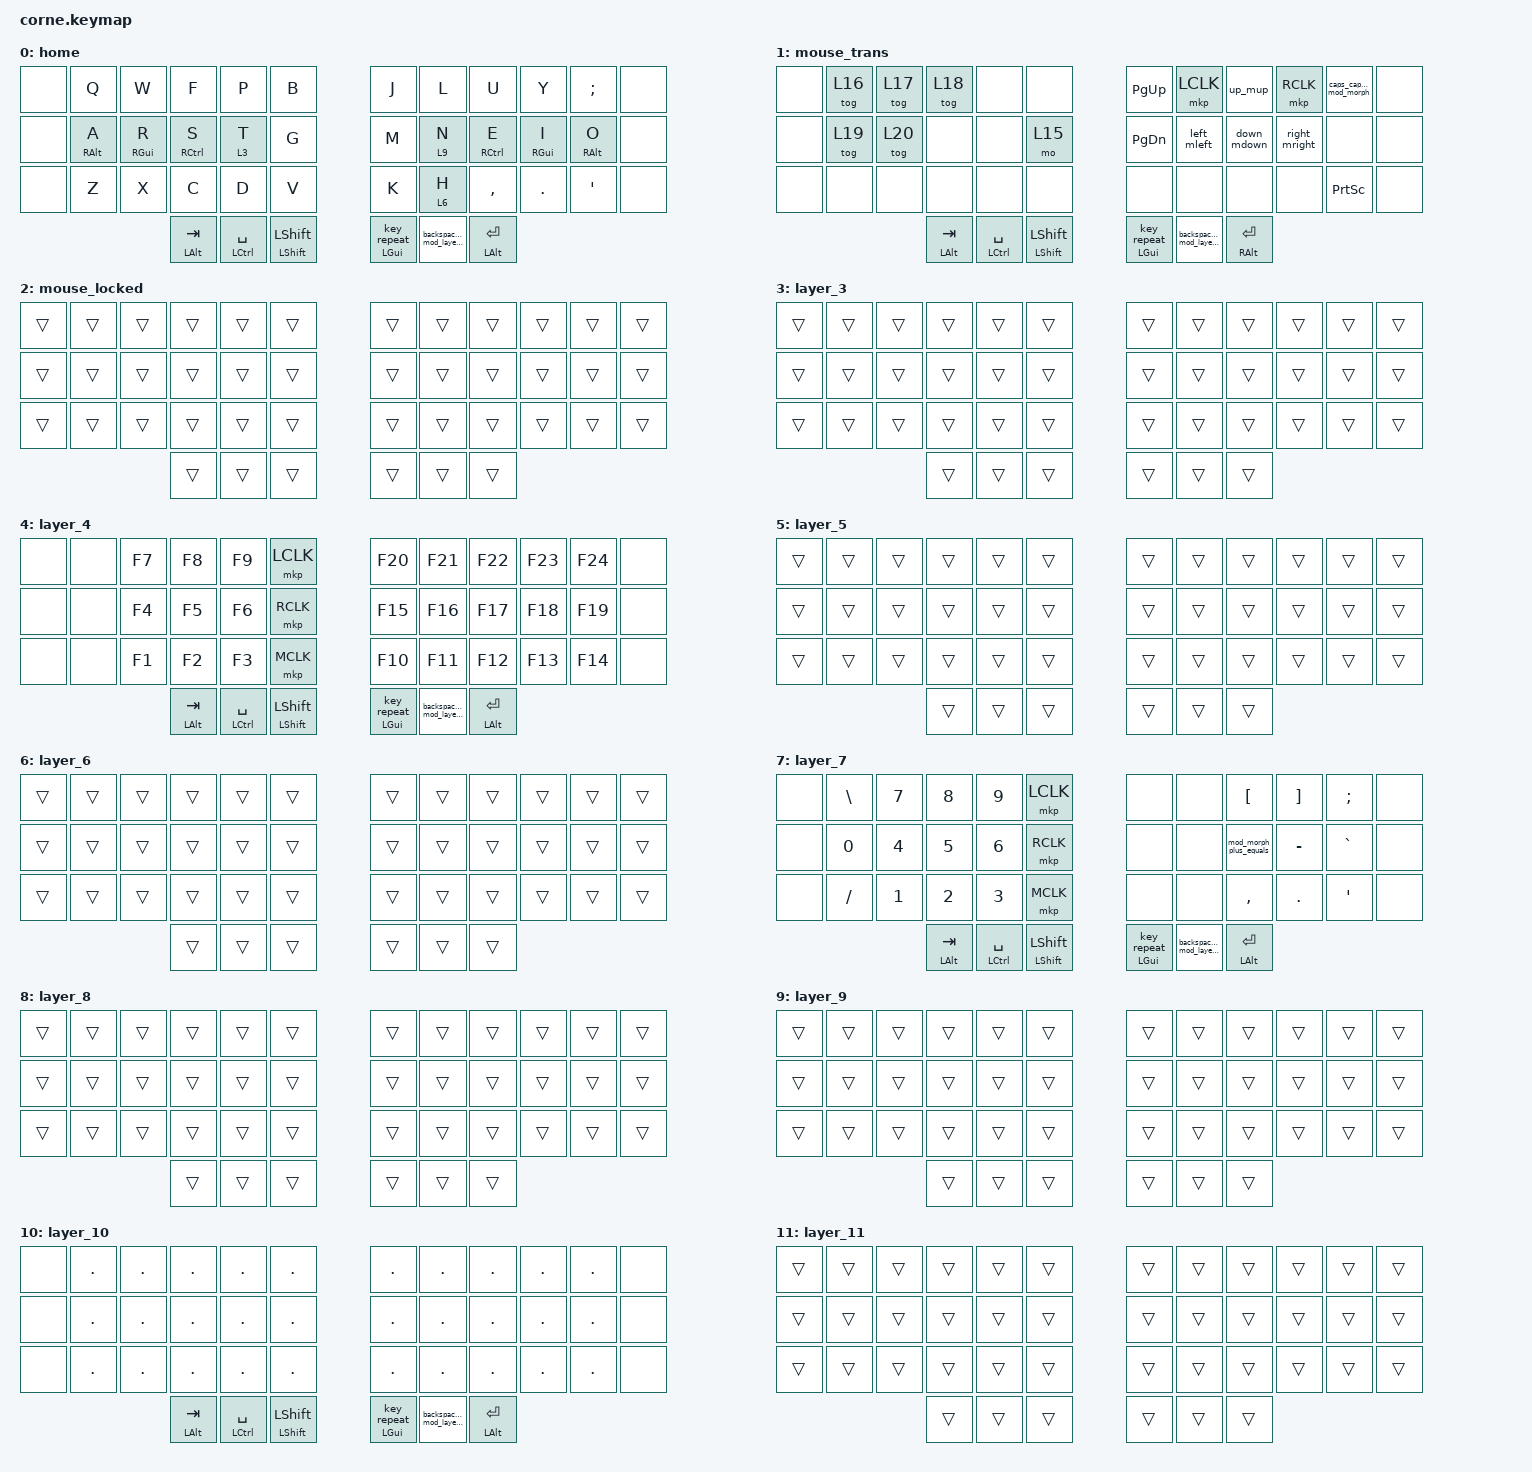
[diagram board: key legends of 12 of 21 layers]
/*
 * Copyright (c) 2020 The ZMK Contributors
 *
 * SPDX-License-Identifier: MIT
 */

#include <behaviors.dtsi>
#include <dt-bindings/zmk/bt.h>
#include <dt-bindings/zmk/keys.h>
#include <dt-bindings/zmk/mouse.h>

/ {
    behaviors {
        hold_tap_mo_kp: hold_tap_mo_kp {
            compatible = "zmk,behavior-hold-tap";
            label = "HOLD_TAP_MO_KP";
            bindings = <&mo>, <&kp>;

            #binding-cells = <2>;
            tapping-term-ms = <180>;
            flavor = "balanced";
            quick-tap-ms = <150>;
        };

        hold_tap_kp_kp: hold_tap_kp_kp {
            compatible = "zmk,behavior-hold-tap";
            label = "HOLD_TAP_KP_KP";
            bindings = <&kp>, <&kp>;

            #binding-cells = <2>;
            tapping-term-ms = <280>;
            flavor = "balanced";
            quick-tap-ms = <175>;
            require-prior-idle-ms = <135>;
            hold-while-undecided;
        };

        hold_tap_tog_kr: hold_tap_tog_kr {
            compatible = "zmk,behavior-hold-tap";
            label = "HOLD_TAP_TOG_KR";
            #binding-cells = <2>;
            tapping-term-ms = <280>;
            flavor = "balanced";
            bindings = <&tog>, <&key_repeat>;

            quick-tap-ms = <175>;
            require-prior-idle-ms = <135>;
            hold-while-undecided;
        };

        hold_tap_kp_kr: hold_tap_kp_kr {
            compatible = "zmk,behavior-hold-tap";
            label = "HOLD_TAP_KP_KR";
            #binding-cells = <2>;
            tapping-term-ms = <280>;
            flavor = "balanced";
            bindings = <&kp>, <&key_repeat>;

            quick-tap-ms = <175>;
            require-prior-idle-ms = <135>;
            hold-while-undecided;
        };

        sticky_key: sticky_key {
            compatible = "zmk,behavior-sticky-key";
            label = "STICKY_KEY";
            bindings = <&kp>;
            #binding-cells = <1>;
            quick-release;
            release-after-ms = <200>;
        };

        hold_tap_sk_kp: hold_tap_sk_kp {
            compatible = "zmk,behavior-hold-tap";
            label = "HOLD_TAP_SK_KP";
            bindings = <&sticky_key>, <&kp>;

            #binding-cells = <2>;
            tapping-term-ms = <280>;
            quick-tap-ms = <175>;
            flavor = "balanced";
            require-prior-idle-ms = <135>;
            hold-while-undecided;
        };

        hold_tap_kp_sk: hold_tap_kp_sk {
            compatible = "zmk,behavior-hold-tap";
            label = "HOLD_TAP_KP_SK";
            bindings = <&kp>, <&sticky_key>;

            #binding-cells = <2>;
            tapping-term-ms = <280>;
            flavor = "balanced";
            quick-tap-ms = <175>;
            require-prior-idle-ms = <135>;
            hold-while-undecided-linger;
        };

        hold_tap_tog_kp: hold_tap_tog_kp {
            compatible = "zmk,behavior-hold-tap";
            label = "HOLD_TAP_TOG_KP";
            bindings = <&tog>, <&kp>;

            #binding-cells = <2>;
            tapping-term-ms = <280>;
            flavor = "balanced";
            quick-tap-ms = <175>;
            require-prior-idle-ms = <135>;
            hold-while-undecided;
        };

        backspace_del_mod_layer_1: backspace_del_mod_layer_1 {
            compatible = "zmk,behavior-mod-morph";
            label = "BACKSPACE_DEL_MOD_LAYER_1";
            bindings = <&kp BACKSPACE>, <&kp DELETE>;

            #binding-cells = <0>;
            mods = <(MOD_LALT)>;
        };

        backspace_del_mod_layer_3: backspace_del_mod_layer_3 {
            compatible = "zmk,behavior-mod-morph";
            label = "BACKSPACE_DEL_MOD_LAYER_3";
            bindings =
                <&hold_tap_tog_kp 5 BACKSPACE>,
                <&hold_tap_tog_kp 5 DELETE>;

            #binding-cells = <0>;
            mods = <(MOD_LALT)>;
        };

        backspace_del_mod_layer_5: backspace_del_mod_layer_5 {
            compatible = "zmk,behavior-mod-morph";
            label = "BACKSPACE_DEL_MOD_LAYER_5";
            bindings =
                <&hold_tap_tog_kp 11 BACKSPACE>,
                <&hold_tap_tog_kp 11 DELETE>;

            #binding-cells = <0>;
            mods = <(MOD_LALT)>;
        };

        backspace_del_mod_layer_2: backspace_del_mod_layer_2 {
            compatible = "zmk,behavior-mod-morph";
            label = "BACKSPACE_DEL_MOD_LAYER_2";
            bindings =
                <&hold_tap_tog_kp 2 BACKSPACE>,
                <&hold_tap_tog_kp 2 DELETE>;

            #binding-cells = <0>;
            mods = <(MOD_LALT)>;
        };

        backspace_del_mod_layer_4: backspace_del_mod_layer_4 {
            compatible = "zmk,behavior-mod-morph";
            label = "BACKSPACE_DEL_MOD_LAYER_4";
            bindings =
                <&hold_tap_tog_kp 8 BACKSPACE>,
                <&hold_tap_tog_kp 8 DELETE>;

            #binding-cells = <0>;
            mods = <(MOD_LALT)>;
        };

        backspace_del_mod_layer_6: backspace_del_mod_layer_6 {
            compatible = "zmk,behavior-mod-morph";
            label = "BACKSPACE_DEL_MOD_LAYER_6";
            bindings =
                <&hold_tap_tog_kp 14 BACKSPACE>,
                <&hold_tap_tog_kp 14 DELETE>;

            #binding-cells = <0>;
            mods = <(MOD_LALT)>;
        };

        hold_tap_no_kp: hold_tap_no_kp {
            compatible = "zmk,behavior-hold-tap";
            label = "HOLD_TAP_NO_KP";
            bindings = <&kp>, <&kp>;

            #binding-cells = <2>;
            tapping-term-ms = <280>;
            flavor = "balanced";
            quick-tap-ms = <175>;
            require-prior-idle-ms = <135>;
            hold-while-undecided;
        };

        capsword: capsword {
            compatible = "zmk,behavior-caps-word";
            label = "CAPSWORD";
            #binding-cells = <0>;
            continue-list = <A B D C E F G H I J K L M N O P Q R S T U V W X Y Z>;
        };

        caps_capsword_mod_morph: caps_capsword_mod_morph {
            compatible = "zmk,behavior-mod-morph";
            label = "CAPS_CAPSWORD_MOD_MORPH";
            bindings = <&kp CAPSLOCK>, <&capsword>;

            #binding-cells = <0>;
            mods = <(MOD_LALT)>;
        };

        left_mleft: left_mleft {
            compatible = "zmk,behavior-mod-morph";
            label = "LEFT_MLEFT";
            bindings = <&kp LEFT>, <U_MS_L>;

            #binding-cells = <0>;
            mods = <(MOD_RALT)>;
        };

        right_mright: right_mright {
            compatible = "zmk,behavior-mod-morph";
            label = "RIGHT_MRIGHT";
            bindings = <&kp RIGHT>, <U_MS_R>;

            #binding-cells = <0>;
            mods = <(MOD_RALT)>;
        };

        up_mup: up_mup {
            compatible = "zmk,behavior-mod-morph";
            label = "UP_MUP";
            bindings = <&kp UP>, <U_MS_U>;

            #binding-cells = <0>;
            mods = <(MOD_RALT)>;
        };

        down_mdown: down_mdown {
            compatible = "zmk,behavior-mod-morph";
            label = "DOWN_MDOWN";
            bindings = <&kp DOWN_ARROW>, <U_MS_D>;

            #binding-cells = <0>;
            mods = <(MOD_RALT)>;
        };

        hold_tap_kp_kp_homerow_left: hold_tap_kp_kp_homerow_left {
            compatible = "zmk,behavior-hold-tap";
            label = "HOLD_TAP_KP_KP_HOMEROW_LEFT";
            bindings = <&kp>, <&kp>;

            #binding-cells = <2>;
            tapping-term-ms = <280>;
            flavor = "balanced";
            quick-tap-ms = <175>;
            require-prior-idle-ms = <135>;
            hold-while-undecided;
        };

        mod_morph_tab_1: mod_morph_tab_1 {
            compatible = "zmk,behavior-mod-morph";
            label = "MOD_MORPH_TAB_1";
            bindings = <&kp TAB>, <&kp NUMBER_1>;

            #binding-cells = <0>;
            mods = <(MOD_LALT)>;
            keep-mods = <(MOD_LALT)>;
        };

        mod_morph_a_3: mod_morph_a_3 {
            compatible = "zmk,behavior-mod-morph";
            label = "MOD_MORPH_A_3";
            bindings = <&kp A>, <&kp NUMBER_3>;

            #binding-cells = <0>;
            mods = <(MOD_LALT)>;
            keep-mods = <(MOD_LALT)>;
        };

        mod_morph_d_4: mod_morph_d_4 {
            compatible = "zmk,behavior-mod-morph";
            label = "MOD_MORPH_D_4";
            bindings = <&kp D>, <&kp NUMBER_4>;

            #binding-cells = <0>;
            mods = <(MOD_LALT)>;
            keep-mods = <(MOD_LALT)>;
        };

        mod_morph_g_2: mod_morph_g_2 {
            compatible = "zmk,behavior-mod-morph";
            label = "MOD_MORPH_G_2";
            bindings = <&kp G>, <&kp NUMBER_2>;

            #binding-cells = <0>;
            mods = <(MOD_LALT)>;
            keep-mods = <(MOD_LALT)>;
        };

        mod_morph_r_5: mod_morph_r_5 {
            compatible = "zmk,behavior-mod-morph";
            label = "MOD_MORPH_R_5";
            bindings = <&kp R>, <&kp N5>;

            #binding-cells = <0>;
            mods = <(MOD_LALT)>;
            keep-mods = <(MOD_LALT)>;
        };

        mod_morph_f_6: mod_morph_f_6 {
            compatible = "zmk,behavior-mod-morph";
            label = "MOD_MORPH_F_6";
            bindings = <&kp F>, <&kp NUMBER_6>;

            #binding-cells = <0>;
            mods = <(MOD_LALT)>;
            keep-mods = <(MOD_LALT)>;
        };

        mod_morph_plus_equals: mod_morph_plus_equals {
            compatible = "zmk,behavior-mod-morph";
            label = "MOD_MORPH_PLUS_EQUALS";
            bindings = <&kp PLUS>, <&kp EQUAL>;

            #binding-cells = <0>;
            mods = <(MOD_LSFT|MOD_RSFT)>;
        };

        hold_tap_kp_kp_homerow_right: hold_tap_kp_kp_homerow_right {
            compatible = "zmk,behavior-hold-tap";
            label = "HOLD_TAP_KP_KP_HOMEROW_RIGHT";
            bindings = <&kp>, <&kp>;

            #binding-cells = <2>;
            tapping-term-ms = <280>;
            flavor = "balanced";
            quick-tap-ms = <175>;
            require-prior-idle-ms = <135>;
            hold-while-undecided;
        };
    };

    combos {
        compatible = "zmk,combos";

        end {
            bindings = <&kp END>;
            key-positions = <27 28 38>;
        };

        home {
            bindings = <&kp HOME>;
            key-positions = <27 28 37>;
        };

        esc-left {
            bindings = <&kp ESCAPE>;
            key-positions = <16 15 37>;
        };

        esc-right {
            bindings = <&kp ESCAPE>;
            key-positions = <20 19 40>;
        };

        home-arrow {
            bindings = <&kp HOME>;
            key-positions = <27 37>;
            layers = <1 2 3>;
        };

        end-arrow {
            bindings = <&kp END>;
            key-positions = <27 38>;
            layers = <1 2 3>;
        };

        end-right {
            bindings = <&kp END>;
            key-positions = <31 32 40>;
        };

        home-right {
            bindings = <&kp HOME>;
            key-positions = <39 31 32>;
        };

        esc-left-arrow {
            bindings = <&kp ESCAPE>;
            key-positions = <15 37>;
            layers = <2 1 3>;
        };

        esc-right-symbol-function {
            bindings = <&kp ESCAPE>;
            key-positions = <20 40>;
            layers = <9 7 8 4 5 6>;
        };

        end-right-symbol-function {
            bindings = <&kp END>;
            key-positions = <32 40>;
            layers = <7 8 9 4 5 6>;
        };

        home-right-symbol-function {
            bindings = <&kp HOME>;
            key-positions = <39 32>;
            layers = <7 8 9 4 5 6>;
        };
    };

    keymap {
        compatible = "zmk,keymap";

        home {
            // -----------------------------------------------------------------------------------------
            // |  TAB |  Q  |  W  |  E  |  R  |  T  |   |  Y  |  U   |  I  |  O  |  P  | BKSP |
            // | CTRL |  A  |  S  |  D  |  F  |  G  |   |  H  |  J   |  K  |  L  |  ;  |  '   |
            // | SHFT |  Z  |  X  |  C  |  V  |  B  |   |  N  |  M   |  ,  |  .  |  /  | ESC  |
            //                    | GUI | LWR | SPC |   | ENT | RSE  | ALT |

            bindings = <
&none  &kp Q                                     &kp W                                     &kp F                                 &kp P                        &kp B                                    &kp J                       &kp L                       &kp U                                  &kp Y                                      &kp SEMICOLON                              &none
&none  &hold_tap_kp_kp_homerow_left RIGHT_ALT A  &hold_tap_kp_kp_homerow_left RIGHT_GUI R  &hold_tap_kp_kp_homerow_left RCTRL S  &hold_tap_mo_kp 3 T          &kp G                                    &kp M                       &hold_tap_mo_kp 9 N         &hold_tap_kp_kp_homerow_right RCTRL E  &hold_tap_kp_kp_homerow_right RIGHT_GUI I  &hold_tap_kp_kp_homerow_right RIGHT_ALT O  &none
&none  &kp Z                                     &kp X                                     &kp C                                 &kp D                        &kp V                                    &kp K                       &hold_tap_mo_kp 6 H         &kp COMMA                              &kp DOT                                    &kp APOS                                   &none
                                                                                           &hold_tap_kp_kp LEFT_ALT TAB          &hold_tap_kp_kp LCTRL SPACE  &hold_tap_kp_sk LEFT_SHIFT LEFT_SHIFT    &hold_tap_kp_kr LEFT_GUI 0  &backspace_del_mod_layer_1  &hold_tap_kp_kp LEFT_ALT ENTER
            >;
        };

        mouse_trans {
            bindings = <
&none  &tog 16  &tog 17  &tog 18                       &none                        &none                            &kp PG_UP               &mkp LCLK                    &up_mup                          &mkp RCLK       &caps_capsword_mod_morph  &none
&none  &tog 19  &tog 20  &none                         &none                        &mo 15                           &kp PAGE_DOWN           &left_mleft                 &down_mdown                      &right_mright  &none                     &none
&none  &none    &none    &none                         &none                        &none                            &none                   &none                       &none                            &none          &kp PRINTSCREEN           &none
                         &hold_tap_kp_kp LEFT_ALT TAB  &hold_tap_kp_kp LCTRL SPACE  &hold_tap_kp_sk LSHIFT LSHIFT    &hold_tap_kp_kr LGUI 0  &backspace_del_mod_layer_2  &hold_tap_kp_kp RIGHT_ALT ENTER
            >;
        };

        mouse_locked {
            bindings = <
&trans  &trans  &trans  &trans  &trans  &trans    &trans  &trans  &trans  &trans  &trans  &trans
&trans  &trans  &trans  &trans  &trans  &trans    &trans  &trans  &trans  &trans  &trans  &trans
&trans  &trans  &trans  &trans  &trans  &trans    &trans  &trans  &trans  &trans  &trans  &trans
                        &trans  &trans  &trans    &trans  &trans  &trans
            >;
        };

        layer_3 {
            bindings = <
&trans  &trans  &trans  &trans  &trans  &trans    &trans  &trans  &trans  &trans  &trans  &trans
&trans  &trans  &trans  &trans  &trans  &trans    &trans  &trans  &trans  &trans  &trans  &trans
&trans  &trans  &trans  &trans  &trans  &trans    &trans  &trans  &trans  &trans  &trans  &trans
                        &trans  &trans  &trans    &trans  &trans  &trans
            >;
        };

        layer_4 {
            bindings = <
&none  &none  &kp F7  &kp F8                        &kp F9                       &mkp LCLK                                 &kp F20                     &kp F21                     &kp F22                         &kp F23  &kp F24  &none
&none  &none  &kp F4  &kp F5                        &kp F6                       &mkp RCLK                                 &kp F15                     &kp F16                     &kp F17                         &kp F18  &kp F19  &none
&none  &none  &kp F1  &kp F2                        &kp F3                       &mkp MCLK                                 &kp F10                     &kp F11                     &kp F12                         &kp F13  &kp F14  &none
                      &hold_tap_kp_kp LEFT_ALT TAB  &hold_tap_kp_kp LCTRL SPACE  &hold_tap_kp_sk LEFT_SHIFT LEFT_SHIFT    &hold_tap_kp_kr LEFT_GUI 0  &backspace_del_mod_layer_3  &hold_tap_kp_kp LEFT_ALT ENTER
            >;
        };

        layer_5 {
            bindings = <
&trans  &trans  &trans  &trans  &trans  &trans    &trans  &trans  &trans  &trans  &trans  &trans
&trans  &trans  &trans  &trans  &trans  &trans    &trans  &trans  &trans  &trans  &trans  &trans
&trans  &trans  &trans  &trans  &trans  &trans    &trans  &trans  &trans  &trans  &trans  &trans
                        &trans  &trans  &trans    &trans  &trans  &trans
            >;
        };

        layer_6 {
            bindings = <
&trans  &trans  &trans  &trans  &trans  &trans    &trans  &trans  &trans  &trans  &trans  &trans
&trans  &trans  &trans  &trans  &trans  &trans    &trans  &trans  &trans  &trans  &trans  &trans
&trans  &trans  &trans  &trans  &trans  &trans    &trans  &trans  &trans  &trans  &trans  &trans
                        &trans  &trans  &trans    &trans  &trans  &trans
            >;
        };

        layer_7 {
            bindings = <
&none  &kp BACKSLASH  &kp N7        &kp N8                        &kp N9                       &mkp LCLK                                 &none                       &none                       &kp LEFT_BRACKET                &kp RIGHT_BRACKET  &kp SEMICOLON  &none
&none  &kp N0         &kp NUMBER_4  &kp N5                        &kp NUMBER_6                 &mkp RCLK                                 &none                       &none                       &mod_morph_plus_equals          &kp MINUS          &kp GRAVE      &none
&none  &kp SLASH      &kp NUMBER_1  &kp NUMBER_2                  &kp NUMBER_3                 &mkp MCLK                                 &none                       &none                       &kp COMMA                       &kp PERIOD         &kp SQT        &none
                                    &hold_tap_kp_kp LEFT_ALT TAB  &hold_tap_kp_kp LCTRL SPACE  &hold_tap_kp_sk LEFT_SHIFT LEFT_SHIFT    &hold_tap_kp_kr LEFT_GUI 0  &backspace_del_mod_layer_4  &hold_tap_kp_kp LEFT_ALT ENTER
            >;
        };

        layer_8 {
            bindings = <
&trans  &trans  &trans  &trans  &trans  &trans    &trans  &trans  &trans  &trans  &trans  &trans
&trans  &trans  &trans  &trans  &trans  &trans    &trans  &trans  &trans  &trans  &trans  &trans
&trans  &trans  &trans  &trans  &trans  &trans    &trans  &trans  &trans  &trans  &trans  &trans
                        &trans  &trans  &trans    &trans  &trans  &trans
            >;
        };

        layer_9 {
            bindings = <
&trans  &trans  &trans  &trans  &trans  &trans    &trans  &trans  &trans  &trans  &trans  &trans
&trans  &trans  &trans  &trans  &trans  &trans    &trans  &trans  &trans  &trans  &trans  &trans
&trans  &trans  &trans  &trans  &trans  &trans    &trans  &trans  &trans  &trans  &trans  &trans
                        &trans  &trans  &trans    &trans  &trans  &trans
            >;
        };

        layer_10 {
            bindings = <
&none  &kp DOT  &kp DOT  &kp DOT                       &kp DOT                      &kp DOT                                  &kp DOT                     &kp DOT                     &kp DOT                         &kp DOT  &kp DOT  &none
&none  &kp DOT  &kp DOT  &kp DOT                       &kp DOT                      &kp DOT                                  &kp DOT                     &kp DOT                     &kp DOT                         &kp DOT  &kp DOT  &none
&none  &kp DOT  &kp DOT  &kp DOT                       &kp DOT                      &kp DOT                                  &kp DOT                     &kp DOT                     &kp DOT                         &kp DOT  &kp DOT  &none
                         &hold_tap_kp_kp LEFT_ALT TAB  &hold_tap_kp_kp LCTRL SPACE  &hold_tap_kp_sk LEFT_SHIFT LEFT_SHIFT    &hold_tap_kp_kr LEFT_GUI 0  &backspace_del_mod_layer_5  &hold_tap_kp_kp LEFT_ALT ENTER
            >;
        };

        layer_11 {
            bindings = <
&trans  &trans  &trans  &trans  &trans  &trans    &trans  &trans  &trans  &trans  &trans  &trans
&trans  &trans  &trans  &trans  &trans  &trans    &trans  &trans  &trans  &trans  &trans  &trans
&trans  &trans  &trans  &trans  &trans  &trans    &trans  &trans  &trans  &trans  &trans  &trans
                        &trans  &trans  &trans    &trans  &trans  &trans
            >;
        };

        layer_12 {
            bindings = <
&trans  &trans  &trans  &trans  &trans  &trans    &trans  &trans  &trans  &trans  &trans  &trans
&trans  &trans  &trans  &trans  &trans  &trans    &trans  &trans  &trans  &trans  &trans  &trans
&trans  &trans  &trans  &trans  &trans  &trans    &trans  &trans  &trans  &trans  &trans  &trans
                        &trans  &trans  &trans    &trans  &trans  &trans
            >;
        };

        layer_13 {
            bindings = <
&none  &kp C_BRIGHTNESS_INC   &kp C_VOLUME_UP    &kp C_NEXT                    &none                        &none                                    &none                       &none                       &none                           &none         &none         &none
&none  &kp C_BRIGHTNESS_DEC   &kp C_VOLUME_DOWN  &kp C_PREVIOUS                &none                        &none                                    &bt BT_SEL 0                &bt BT_SEL 1                &bt BT_SEL 2                    &bt BT_SEL 3  &bt BT_SEL 4  &none
&none  &kp C_BRIGHTNESS_AUTO  &kp C_MUTE         &kp C_PLAY_PAUSE              &none                        &none                                    &none                       &none                       &none                           &none         &bt BT_CLR    &none
                                                 &hold_tap_kp_kp LEFT_ALT TAB  &hold_tap_kp_kp LCTRL SPACE  &hold_tap_kp_sk LEFT_SHIFT LEFT_SHIFT    &hold_tap_kp_kr LEFT_GUI 0  &backspace_del_mod_layer_6  &hold_tap_kp_kp LEFT_ALT ENTER
            >;
        };

        layer_14 {
            bindings = <
&trans  &trans  &trans  &trans  &trans  &trans    &trans  &trans  &trans  &trans  &trans  &trans
&trans  &trans  &trans  &trans  &trans  &trans    &trans  &trans  &trans  &trans  &trans  &trans
&trans  &trans  &trans  &trans  &trans  &trans    &trans  &trans  &trans  &trans  &trans  &trans
                        &trans  &trans  &trans    &trans  &trans  &trans
            >;
        };

        layer_15 {
            bindings = <
&trans  &trans  &trans  &trans  &trans  &trans    &trans  &trans  &trans  &trans  &trans  &trans
&trans  &trans  &trans  &trans  &trans  &trans    &trans  &trans  &trans  &trans  &trans  &trans
&trans  &trans  &trans  &trans  &trans  &trans    &trans  &trans  &trans  &trans  &trans  &trans
                        &trans  &trans  &trans    &trans  &trans  &trans
            >;
        };

        layer_16 {
            bindings = <
&none  &mod_morph_tab_1  &mod_morph_g_2  &kp W         &mod_morph_r_5  &mod_morph_f_6    &none  &none    &none  &none  &none  &none
&none  &kp LEFT_SHIFT    &mod_morph_a_3  &kp S         &mod_morph_d_4  &kp E             &none  &none    &none  &none  &none  &none
&none  &kp M             &kp B           &kp X         &kp H           &kp V             &none  &none    &none  &none  &none  &none
                                         &kp LEFT_ALT  &kp SPACE       &kp LCTRL         &none  &tog 16  &none
            >;
        };

        layer_17 {
            bindings = <
&none  &none  &none  &none  &none  &none    &kp S  &none    &none  &none  &none  &none
&none  &none  &none  &none  &none  &none    &none  &none    &none  &none  &none  &none
&none  &none  &none  &none  &none  &none    &none  &none    &none  &none  &none  &none
                     &none  &none  &none    &none  &tog 17  &none
            >;
        };

        layer_18 {
            bindings = <
&none  &none  &none  &none  &none  &none    &kp O  &none    &none  &none  &none  &none
&none  &none  &none  &none  &none  &none    &none  &none    &none  &none  &none  &none
&none  &none  &none  &none  &none  &none    &none  &none    &none  &none  &none  &none
                     &none  &none  &none    &none  &tog 18  &none
            >;
        };

        layer_19 {
            bindings = <
&none  &none  &none  &none  &none  &none    &kp G  &none    &none  &none  &none  &none
&none  &none  &none  &none  &none  &none    &none  &none    &none  &none  &none  &none
&none  &none  &none  &none  &none  &none    &none  &none    &none  &none  &none  &none
                     &none  &none  &none    &none  &tog 19  &none
            >;
        };

        layer_20 {
            bindings = <
&none  &none  &none  &none  &none  &none    &kp M  &none    &none  &none  &none  &none
&none  &none  &none  &none  &none  &none    &none  &none    &none  &none  &none  &none
&none  &none  &none  &none  &none  &none    &none  &none    &none  &none  &none  &none
                     &none  &none  &none    &none  &tog 20  &none
            >;
        };
    };

    conditional_layers {
        compatible = "zmk,conditional-layers";

        layer_2_lock {
            if-layers = <2>;
            then-layer = <1>;
        };

        layer_2_temp {
            if-layers = <3>;
            then-layer = <1>;
        };

        layer_3_lock {
            if-layers = <5>;
            then-layer = <4>;
        };

        layer_3_temp {
            if-layers = <6>;
            then-layer = <4>;
        };

        layer_4_lock {
            if-layers = <8>;
            then-layer = <7>;
        };

        layer_4_temp {
            if-layers = <9>;
            then-layer = <7>;
        };

        layer_5_lock {
            if-layers = <11>;
            then-layer = <10>;
        };

        layer_5_temp {
            if-layers = <12>;
            then-layer = <10>;
        };

        layer_6_lock {
            if-layers = <14>;
            then-layer = <13>;
        };

        layer_6_temp {
            if-layers = <15>;
            then-layer = <13>;
        };
    };
};
